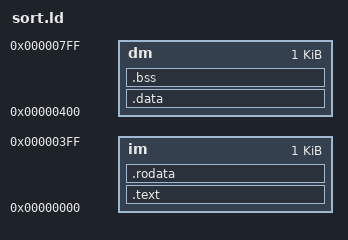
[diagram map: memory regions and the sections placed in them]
/* =============================================================================
 * sort.ld —— 把这段程序钉在这颗核的地址图上
 *
 * 第 9 集的 cpu_top 是哈佛结构：im 与 dm 各走各的读口，各自从 0 开始数自己的字节。
 * 但链接器只有一个地址空间，所以这里给两块存储各划一段：
 *   im  0x000..0x3FF   1KB —— 256 字 × 32 位（取指只看 pc[9:2]）
 *   dm  0x400..0x7FF   1KB —— dm 的后半；前半是第 9 集那台自测程序写 dm[0] 的地方
 * dm 一共 2KB（访存只看 ex.result[10:3]），所以 0x400 起这 1KB 是它的合法窗口，
 * 越过 0x800 就绕回 0 —— 地址图的边界是硬件给的，不是链接脚本说了算。
 *
 * .bss 不需要镜像：dm 的复位值本来就是 0（memory.prism 里 `mem ram : [SIZE] W = 0`），
 * 清零这一段交给硬件，编译器只管有初值的 .data。
 * ============================================================================= */

ENTRY(sort)

MEMORY {
    im : ORIGIN = 0x00000000, LENGTH = 1K
    dm : ORIGIN = 0x00000400, LENGTH = 1K
}

SECTIONS {
    .text   : { *(.text*) }              > im
    .rodata : { *(.rodata*) }            > im
    .data   : { *(.data*) *(.sdata*) }   > dm
    .bss    : { *(.bss*) *(.sbss*) *(COMMON) } > dm
}
